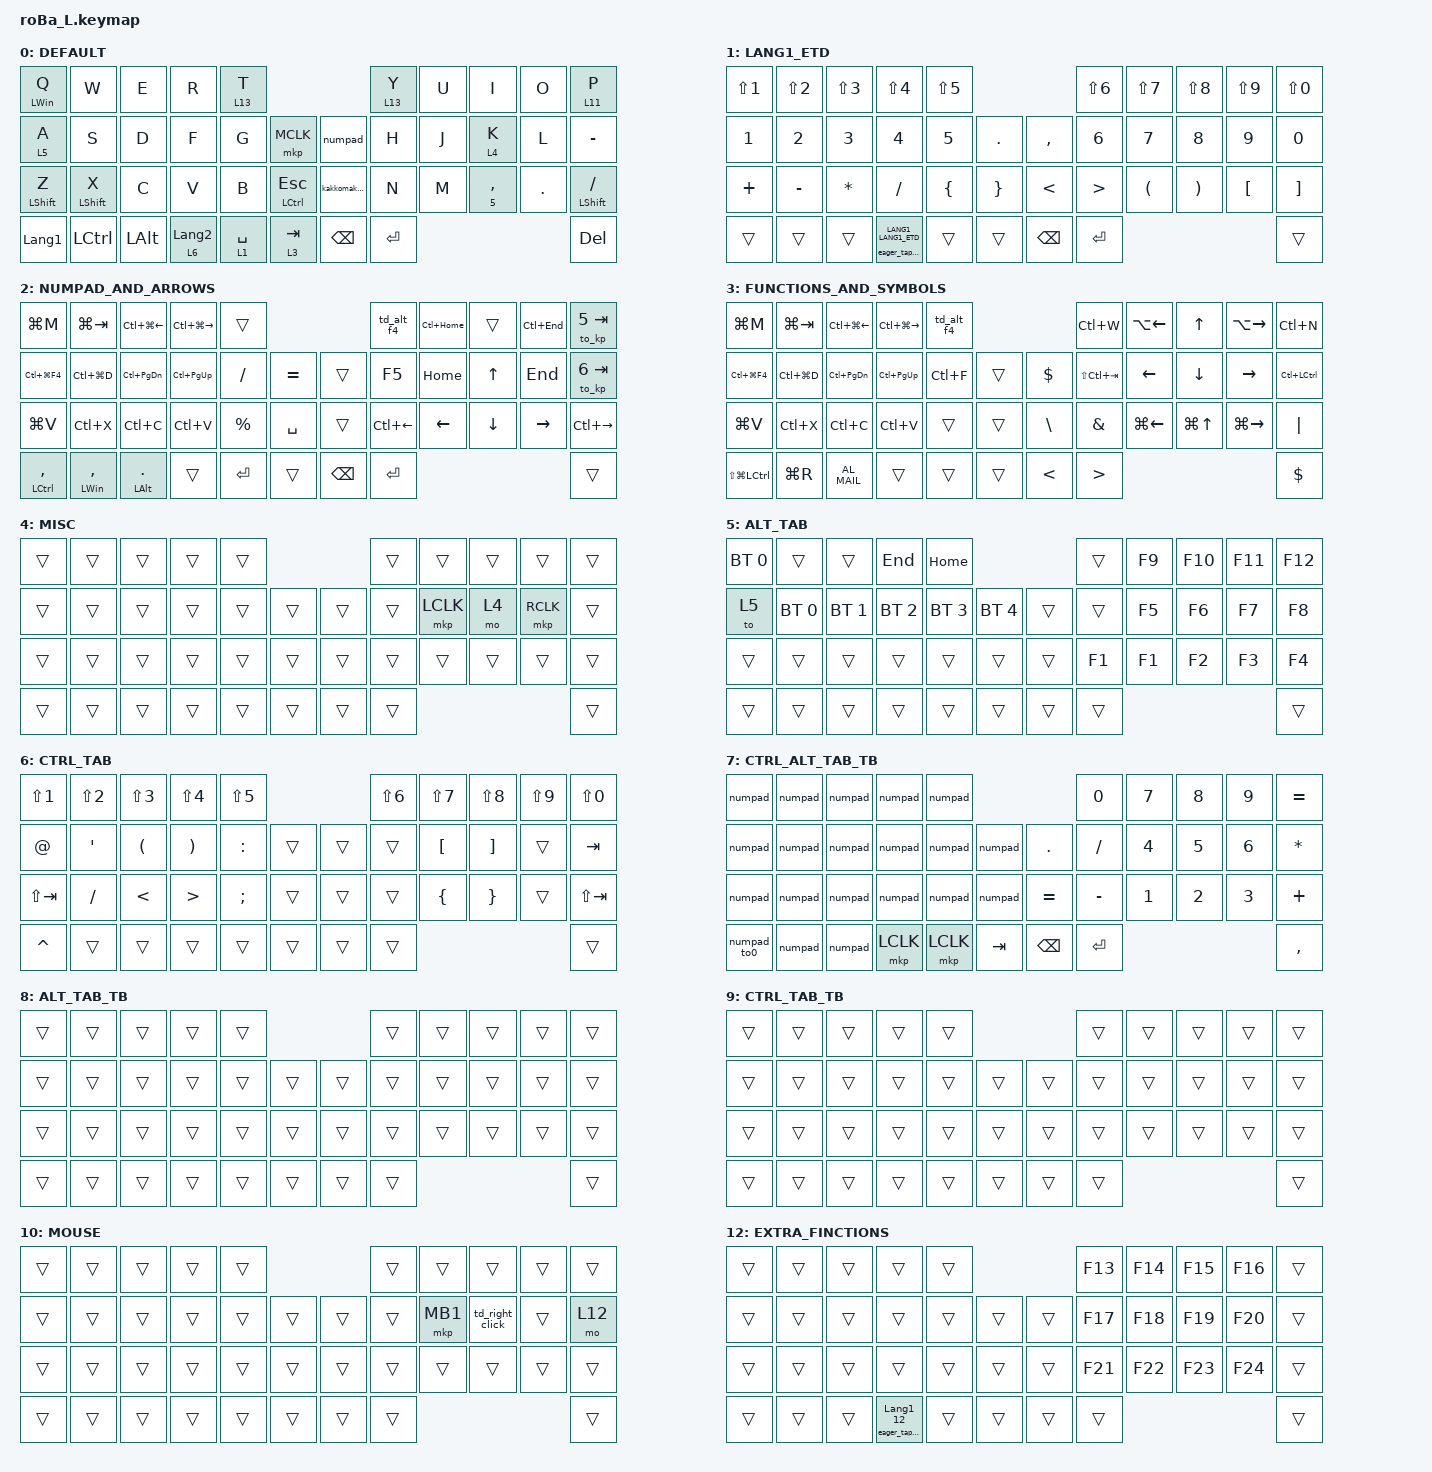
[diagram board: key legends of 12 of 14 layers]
#define ZMK_POINTING_DEFAULT_SCRL_VAL 100

// #define ZMK_POINTING_DEFAULT_MOVE_VAL 700

#include <input/processors.dtsi>
#include <behaviors/rgbled_widget.dtsi>
#include <behaviors.dtsi>
#include <dt-bindings/zmk/backlight.h>
#include <dt-bindings/zmk/bt.h>
#include <dt-bindings/zmk/keys.h>
#include <dt-bindings/zmk/outputs.h>
#include <dt-bindings/zmk/pointing.h>

#define DEFAULT 0
#define LANG1_ETD 1
#define NUMPAD_AND_ARROWS 2
#define FUNCTIONS_AND_SYMBOLS 3
#define MISC 4
#define ALT_TAB 5
#define CTRL_TAB 6
#define CTRL_ALT_TAB_TB 7
#define ALT_TAB_TB 8
#define CTRL_TAB_TB 9
#define MOUSE 10
#define MEDIA 11
#define EXTRA_FINCTIONS 12
#define CONFIGURATION 13

&mt {
    tapping-term-ms = <200>;
    quick-tap-ms = <250>;
    flavor = "balanced";
};

&lt {
    tapping-term-ms = <200>;
    quick-tap-ms = <250>;
    flavor = "balanced";
};

&sk { release-after-ms = <700>; };

&sl { release-after-ms = <1000>; };

&mkp_input_listener { input-processors = <&zip_temp_layer MOUSE 10000>; };

/ {
    layer_listeners {
        compatible = "zmk,layer-listeners";

        release_alt {
            layers = <ALT_TAB ALT_TAB_TB>;
            bindings = <&kt_on LEFT_ALT &kt_off LEFT_ALT>;
        };

        release_ctrl {
            layers = <CTRL_TAB CTRL_TAB_TB>;
            bindings = <&kt_on LCTRL &kt_off LCTRL>;
        };

        // AML_indicator {
        //     layers = <MOUSE>;
        //     bindings = <&kp LS(LA(LC(LG(H)))) &kp LS(LA(LC(LG(H))))>;
        // };
        // AML {
        //     layers = <MOUSE>;
        //     bindings = <&to MOUSE &none>;
        // };
    };

    combos {
        compatible = "zmk,combos";

        eq {
            bindings = <&kp EQUAL>;
            key-positions = <0 1>;
            layers = <2>;
        };

        Escape {
            bindings = <&kp ESCAPE>;
            key-positions = <0 1>;
        };

        hat {
            bindings = <&kp CARET>;
            key-positions = <10 11>;
            layers = <2>;
        };

        L_click {
            bindings = <&mkp LCLK>;
            key-positions = <18 19>;
            layers = <10>;
        };

        caps_word {
            bindings = <&caps_word>;
            key-positions = <22 33>;
        };

        dot_slash_backslash {
            bindings = <&kp BACKSLASH>;
            key-positions = <33 32>;
        };

        R_click {
            bindings = <&mkp RCLK>;
            key-positions = <19 20>;
        };
    };

    macros {
        /omit-if-no-ref/


        /omit-if-no-ref/


        /omit-if-no-ref/


        /omit-if-no-ref/


        /omit-if-no-ref/


        /omit-if-no-ref/

        mo_exit_alttab: mo_exit_alttab_ctrltab {
            compatible = "zmk,behavior-macro-one-param";
            wait-ms = <0>;
            tap-ms = <0>;
            #binding-cells = <1>;
            bindings =
                <&macro_press>,
                <&macro_param_1to1 &mo MACRO_PLACEHOLDER>,
                <&macro_tap>,
                <&macro_pause_for_release>,
                <&macro_release>,
                <&macro_param_1to1 &mo MACRO_PLACEHOLDER>,
                <&macro_tap>,
                <&tog_off ALT_TAB &tog_off CTRL_TAB>;
        };

        /omit-if-no-ref/

        kp_to: kp_to {
            compatible = "zmk,behavior-macro-two-param";
            wait-ms = <0>;
            tap-ms = <0>;
            #binding-cells = <2>;
            bindings = <&macro_param_1to1 &kp MACRO_PLACEHOLDER &macro_param_2to1 &to MACRO_PLACEHOLDER>;
        };

        /omit-if-no-ref/

        to_kp: to_kp {
            compatible = "zmk,behavior-macro-two-param";
            #binding-cells = <2>;
            bindings = <&macro_param_1to1 &to MACRO_PLACEHOLDER &macro_param_2to1 &kp MACRO_PLACEHOLDER>;
        };

        /omit-if-no-ref/

        zoom_in: zoom_in {
            compatible = "zmk,behavior-macro";
            #binding-cells = <0>;
            bindings = <&kt_on LCTRL &msc SCRL_UP &kt_off LCTRL>;
        };

        /omit-if-no-ref/

        zoom_out: zoom_out {
            compatible = "zmk,behavior-macro";
            #binding-cells = <0>;
            bindings = <&kt_on LCTRL &msc SCRL_DOWN &kt_off LCTRL>;
        };

        /omit-if-no-ref/

        eager_tap_dance: eager_tap_dance {
            compatible = "zmk,behavior-macro-two-param";
            #binding-cells = <2>;
            bindings =
                <&macro_press>,
                <&macro_param_1to1 &kp MACRO_PLACEHOLDER>,
                <&macro_pause_for_release>,
                <&macro_release>,
                <&macro_param_1to1 &kp MACRO_PLACEHOLDER>,
                <&macro_tap>,
                <&exit_AML &macro_param_2to1 &sl_250 MACRO_PLACEHOLDER>;
        };
    };

    behaviors {
        /omit-if-no-ref/

        tog_on: toggle_layer_on {
            compatible = "zmk,behavior-toggle-layer";
            #binding-cells = <1>;
            display-name = "Toggle Layer On";
            toggle-mode = "on";
        };

        /omit-if-no-ref/

        tog_off: toggle_layer_off {
            compatible = "zmk,behavior-toggle-layer";
            #binding-cells = <1>;
            display-name = "Toggle Layer Off";
            toggle-mode = "off";
        };

        /omit-if-no-ref/

        kt_on: key_toggle_on_only {
            compatible = "zmk,behavior-key-toggle";
            #binding-cells = <1>;
            display-name = "Key Toggle On";
            toggle-mode = "on";
        };

        /omit-if-no-ref/

        kt_off: key_toggle_off_only {
            compatible = "zmk,behavior-key-toggle";
            #binding-cells = <1>;
            display-name = "Key Toggle Off";
            toggle-mode = "off";
        };

        /omit-if-no-ref/

        td_right_click: td_right_click {
            compatible = "zmk,behavior-tap-dance";
            #binding-cells = <0>;
            bindings = <&mkp RCLK>, <&kp LC(W)>;

            tapping-term-ms = <250>;
        };

        /omit-if-no-ref/

        td_colon: td_colon {
            compatible = "zmk,behavior-tap-dance";
            #binding-cells = <0>;
            bindings = <&kp COLON>, <&kp SEMICOLON>;

            tapping-term-ms = <250>;
        };

        /omit-if-no-ref/

        td_q_escape: td_q_escape {
            compatible = "zmk,behavior-tap-dance";
            #binding-cells = <0>;
            tapping-term-ms = <250>;
            bindings = <&kp Q>, <&kp ESCAPE>;
        };

        /omit-if-no-ref/

        td_ZenkakuHankaku: td_ZenkakuHankaku {
            compatible = "zmk,behavior-tap-dance";

            // compatible = "zmk,behavior-eager-tap-dance";

            #binding-cells = <0>;
            tapping-term-ms = <250>;
            bindings = <&kp LANGUAGE_2>, <&kp LANGUAGE_1>;
        };

        /omit-if-no-ref/

        td_ZenkakuHankaku_exit_AML: td_ZenkakuHankaku_exit_AML {
            wait-ms = <0>;
            tap-ms = <0>;
            compatible = "zmk,behavior-macro";
            #binding-cells = <0>;
            bindings = <&td_ZenkakuHankaku &exit_AML>;
        };

        /omit-if-no-ref/

        alt_tab: alt_tab {
            compatible = "zmk,behavior-macro-two-param";
            #binding-cells = <2>;
            bindings = <&macro_param_1to1 &kt_on MACRO_PLACEHOLDER &macro_param_2to1 &kp MACRO_PLACEHOLDER &macro_param_1to1 &sk MACRO_PLACEHOLDER &macro_param_1to1 &kt_off MACRO_PLACEHOLDER>;
        };

        /omit-if-no-ref/

        windows_sleep: windows_sleep {
            compatible = "zmk,behavior-macro";
            wait-ms = <200>;
            tap-ms = <100>;
            #binding-cells = <0>;
            bindings = <&kp LG(X) &kp U &kp S>;
        };

        /omit-if-no-ref/

        screensot_save: screensot_save {
            compatible = "zmk,behavior-macro";
            #binding-cells = <0>;
            bindings = <&kp LS(F11)>;
            label = "SCREENSOT_SAVE";
        };

        numpad: numpad {
            compatible = "zmk,behavior-macro";
            #binding-cells = <0>;
            bindings = <&kp KP_NUMLOCK &to 7>;
            label = "NUMPAD";
        };

        numpad_to0: numpad_to0 {
            compatible = "zmk,behavior-macro";
            #binding-cells = <0>;
            bindings = <&kp KP_NUMLOCK &to 0>;
            label = "NUMPAD_TO0";
        };

        kakkomakuro: kakkomakuro {
            compatible = "zmk,behavior-macro";
            #binding-cells = <0>;
            bindings = <&kp LANGUAGE_2 &kp LEFT_PARENTHESIS &kp RIGHT_PARENTHESIS &kp ENTER &kp LEFT_ARROW>;
            label = "KAKKOMAKURO";
        };

        new_macro: new_macro {
            compatible = "zmk,behavior-macro";
            #binding-cells = <0>;
            bindings = <&none>;
            label = "NEW_MACRO";
        };

        /omit-if-no-ref/

        screenshot_copy: screenshot_copy {
            compatible = "zmk,behavior-mod-morph";
            bindings = <&kp LA(PRINTSCREEN)>, <&kp LA(PRINTSCREEN)>;

            #binding-cells = <0>;
            mods = <(MOD_LSFT|MOD_LALT)>;
            keep-mods = <(MOD_LALT)>;
        };

        /omit-if-no-ref/

        mod_morph_exclamation: mod_morph_exclamation {
            compatible = "zmk,behavior-mod-morph";
            bindings = <&kp COMMA>, <&kp EXCL>;

            #binding-cells = <0>;
            mods = <(MOD_LSFT)>;
        };

        /omit-if-no-ref/

        mod_morph_question: mod_morph_question {
            compatible = "zmk,behavior-mod-morph";
            bindings = <&kp PERIOD>, <&kp QUESTION>;

            #binding-cells = <0>;
            mods = <(MOD_LSFT)>;
        };

        /omit-if-no-ref/

        mod_morph_slash: mod_morph_slash {
            compatible = "zmk,behavior-mod-morph";
            bindings = <&kp SLASH>, <&kp BACKSLASH>;

            #binding-cells = <0>;
            mods = <(MOD_LSFT)>;
        };

        /omit-if-no-ref/

        td_alt_f4: td_alt_f4 {
            compatible = "zmk,behavior-tap-dance";
            #binding-cells = <0>;
            bindings = <&kp F4>, <&kp LA(F4)>;

            tapping-term-ms = <250>;
        };

        /omit-if-no-ref/

        lt_exit_AML: lt_exit_AML {
            compatible = "zmk,behavior-hold-tap";
            bindings = <&mo_exit_AML>, <&kp_exit_AML>;

            #binding-cells = <2>;
            tapping-term-ms = <200>;
            quick-tap-ms = <200>;
            flavor = "balanced";
        };

        /omit-if-no-ref/

        lt_exit_AML_on_hold: lt_exit_AML_on_hold {
            compatible = "zmk,behavior-hold-tap";
            bindings = <&mo_exit_AML>, <&kp>;

            #binding-cells = <2>;
            tapping-term-ms = <200>;
            quick-tap-ms = <200>;
            flavor = "balanced";
        };

        /omit-if-no-ref/

        lt_exit_alttab: lt_exit_alttab_ctrltab_on_hold_release {
            compatible = "zmk,behavior-hold-tap";
            bindings = <&mo_exit_alttab>, <&kp>;

            #binding-cells = <2>;
            tapping-term-ms = <200>;
            quick-tap-ms = <200>;
            flavor = "balanced";
        };

        /omit-if-no-ref/

        mt_exit_AML: mt_exit_AML {
            compatible = "zmk,behavior-hold-tap";
            bindings = <&mod_exit_AML>, <&kp_exit_AML>;

            #binding-cells = <2>;
            tapping-term-ms = <200>;
            flavor = "balanced";
            quick-tap-ms = <200>;
        };

        /omit-if-no-ref/

        mt_exit_AML_on_tap: mt_exit_AML_on_tap {
            compatible = "zmk,behavior-hold-tap";
            bindings = <&kp>, <&kp_exit_AML>;

            #binding-cells = <2>;
            tapping-term-ms = <200>;
            flavor = "balanced";
            quick-tap-ms = <200>;
        };

        /omit-if-no-ref/

        encoder_zoom: encoder_zoom {
            compatible = "zmk,behavior-sensor-rotate";
            #sensor-binding-cells = <0>;
            bindings = <&zoom_out>, <&zoom_in>;
        };

        /omit-if-no-ref/

        encoder_volume: encoder_volume {
            compatible = "zmk,behavior-sensor-rotate";
            #sensor-binding-cells = <0>;
            bindings = <&kp C_VOLUME_DOWN>, <&kp C_VOLUME_UP>;
        };

        /omit-if-no-ref/

        sl_250: sl_250 {
            compatible = "zmk,behavior-sticky-key";
            bindings = <&mo>;
            #binding-cells = <1>;
            release-after-ms = <250>;
        };

        /omit-if-no-ref/

        td_bt_clear: td_bt_clear {
            compatible = "zmk,behavior-tap-dance";
            #binding-cells = <0>;
            bindings = <&none>, <&none>, <&bt BT_CLR>;

            tapping-term-ms = <250>;
        };

        /omit-if-no-ref/

        td_bt_clear_all: td_bt_clear_all {
            compatible = "zmk,behavior-tap-dance";
            #binding-cells = <0>;
            tapping-term-ms = <250>;
            bindings = <&none>, <&none>, <&bt BT_CLR_ALL>;
        };

        /omit-if-no-ref/

        td_copy_paste: td_copy_paste {
            compatible = "zmk,behavior-tap-dance";
            #binding-cells = <0>;
            bindings = <&kp_exit_AML LC(C)>, <&kp_exit_AML LC(V)>;

            tapping-term-ms = <250>;
        };

        scroll: scroll {
            compatible = "zmk,behavior-sensor-rotate";
            label = "SCROLL";
            #sensor-binding-cells = <0>;
            bindings = <&msc MOVE_X(-5)>, <&msc MOVE_X(5)>;
        };
    };

    keymap {
        compatible = "zmk,keymap";

        DEFAULT {
            bindings = <
&mt LWIN Q                        &kp W             &kp E         &kp R             &lt 13 T                                          &lt 13 Y   &kp U  &kp I                    &kp O    &lt 11 P
&lt 5 A                           &kp S             &kp D         &kp F             &kp G        &mkp MCLK             &numpad        &kp H      &kp J  &lt 4 K                  &kp L    &kp MINUS
&mt_exit_AML_on_tap LEFT_SHIFT Z  &mt LEFT_SHIFT X  &kp C         &kp V             &kp B        &mt LCTRL ESCAPE      &kakkomakuro   &kp N      &kp M  &lt_exit_alttab 5 COMMA  &kp DOT  &mt LEFT_SHIFT SLASH
&kp LANGUAGE_1                    &kp LEFT_CONTROL  &kp LEFT_ALT  &lt 6 LANGUAGE_2  &lt 1 SPACE  &lt 3 TAB             &kp BACKSPACE  &kp ENTER                                           &kp DEL
            >;

            sensor-bindings = <&scroll>;
        };

        LANG1_ETD {
            bindings = <
&kp LS(N1)  &kp LS(N2)  &kp LS(N3)    &kp LS(NUMBER_4)                  &kp LS(N5)                                          &kp LS(N6)        &kp LS(N7)            &kp LS(N8)             &kp LS(NUMBER_9)  &kp LS(N0)
&kp N1      &kp N2      &kp N3        &kp N4                            &kp N5          &kp PERIOD           &kp COMMA      &kp N6            &kp NUMBER_7          &kp N8                 &kp N9            &kp N0
&kp PLUS    &kp MINUS   &kp ASTERISK  &kp SLASH                         &kp LEFT_BRACE  &kp RIGHT_BRACE      &kp LESS_THAN  &kp GREATER_THAN  &kp LEFT_PARENTHESIS  &kp RIGHT_PARENTHESIS  &kp LBKT          &kp RIGHT_BRACKET
&trans      &trans      &trans        &eager_tap_dance LANG1 LANG1_ETD  &trans          &trans               &kp BACKSPACE  &kp ENTER                                                                        &trans
            >;
        };

        NUMPAD_AND_ARROWS {
            bindings = <
&kp LG(M)        &kp LG(TAB)         &kp LC(LG(LEFT_ARROW))  &kp LC(LG(RIGHT_ARROW))  &trans                                     &td_alt_f4    &kp LC(HOME)  &trans        &kp LC(END)  &to_kp 5 TAB
&kp LC(LG(F4))   &kp LC(LG(D))       &kp LC(PAGE_DOWN)       &kp LC(PAGE_UP)          &kp SLASH    &kp EQUAL      &trans         &kp F5        &kp HOME      &kp UP_ARROW  &kp END      &to_kp 6 TAB
&kp LG(V)        &kp LC(X)           &kp LC(C)               &kp LC(V)                &kp PERCENT  &kp SPACE      &trans         &kp LC(LEFT)  &kp LEFT      &kp DOWN      &kp RIGHT    &kp LC(RIGHT)
&mt LCTRL COMMA  &mt LEFT_WIN COMMA  &mt LEFT_ALT PERIOD     &trans                   &kp ENTER    &trans         &kp BACKSPACE  &kp ENTER                                              &trans
            >;

            sensor-bindings =
                <&inc_dec_kp LC(PLUS) LC(MINUS)>,
                <&inc_dec_kp 0 0>;
        };

        FUNCTIONS_AND_SYMBOLS {
            bindings = <
&kp LG(M)          &kp LG(TAB)    &kp LC(LG(LEFT_ARROW))  &kp LC(LG(RIGHT_ARROW))  &td_alt_f4                             &kp LC(W)         &kp LA(LEFT_ARROW)  &kp UP_ARROW      &kp LA(RIGHT_ARROW)  &kp LC(N)
&kp LC(LG(F4))     &kp LC(LG(D))  &kp LC(PAGE_DOWN)       &kp LC(PAGE_UP)          &kp LC(F)   &trans      &kp DOLLAR     &kp LS(LC(TAB))   &kp LEFT_ARROW      &kp DOWN_ARROW    &kp RIGHT_ARROW      &kp LC(LEFT_CONTROL)
&kp LG(V)          &kp LC(X)      &kp LC(C)               &kp LC(V)                &trans      &trans      &kp BSLH       &kp AMPERSAND     &kp LG(LEFT_ARROW)  &kp LG(UP_ARROW)  &kp LG(RIGHT_ARROW)  &kp PIPE
&kp LS(LG(LCTRL))  &kp LG(R)      &kp C_AL_MAIL           &trans                   &trans      &trans      &kp LESS_THAN  &kp GREATER_THAN                                                             &kp DOLLAR
            >;
        };

        MISC {
            bindings = <
&trans  &trans  &trans  &trans  &trans                      &trans  &trans     &trans  &trans     &trans
&trans  &trans  &trans  &trans  &trans  &trans      &trans  &trans  &mkp LCLK  &mo 4   &mkp RCLK  &trans
&trans  &trans  &trans  &trans  &trans  &trans      &trans  &trans  &trans     &trans  &trans     &trans
&trans  &trans  &trans  &trans  &trans  &trans      &trans  &trans                                &trans
            >;

            sensor-bindings = <&scroll>, <&inc_dec_kp 0 0>;
        };

        ALT_TAB {
            bindings = <
&bt BT_SEL 0  &trans        &trans        &kp END       &kp HOME                                &trans  &kp F9  &kp F10  &kp F11  &kp F12
&to 5         &bt BT_SEL 0  &bt BT_SEL 1  &bt BT_SEL 2  &bt BT_SEL 3  &bt BT_SEL 4      &trans  &trans  &kp F5  &kp F6   &kp F7   &kp F8
&trans        &trans        &trans        &trans        &trans        &trans            &trans  &kp F1  &kp F1  &kp F2   &kp F3   &kp F4
&trans        &trans        &trans        &trans        &trans        &trans            &trans  &trans                            &trans
            >;
        };

        CTRL_TAB {
            bindings = <
&kp LS(N1)   &kp LS(N2)  &kp LS(N3)            &kp LS(N4)             &kp LS(N5)                         &kp LS(N6)  &kp LS(N7)        &kp LS(N8)         &kp LS(N9)  &kp LS(N0)
&kp AT_SIGN  &kp SQT     &kp LEFT_PARENTHESIS  &kp RIGHT_PARENTHESIS  &kp COLON      &trans      &trans  &trans      &kp LEFT_BRACKET  &kp RIGHT_BRACKET  &trans      &kp TAB
&kp LS(TAB)  &kp SLASH   &kp LESS_THAN         &kp GREATER_THAN       &kp SEMICOLON  &trans      &trans  &trans      &kp LEFT_BRACE    &kp RIGHT_BRACE    &trans      &kp LS(TAB)
&kp CARET    &trans      &trans                &trans                 &trans         &trans      &trans  &trans                                                       &trans
            >;

            sensor-bindings = <&encoder_zoom>;
        };

        CTRL_ALT_TAB_TB {
            bindings = <
&numpad      &numpad  &numpad  &numpad    &numpad                                &kp NUMBER_0  &kp N7        &kp N8        &kp N9        &kp EQUAL
&numpad      &numpad  &numpad  &numpad    &numpad    &numpad      &kp PERIOD     &kp SLASH     &kp NUMBER_4  &kp N5        &kp NUMBER_6  &kp ASTERISK
&numpad      &numpad  &numpad  &numpad    &numpad    &numpad      &kp EQUAL      &kp MINUS     &kp N1        &kp NUMBER_2  &kp NUMBER_3  &kp PLUS
&numpad_to0  &numpad  &numpad  &mkp LCLK  &mkp LCLK  &kp TAB      &kp BACKSPACE  &kp ENTER                                               &kp COMMA
            >;
        };

        ALT_TAB_TB {
            bindings = <
&trans  &trans  &trans  &trans  &trans                      &trans  &trans  &trans  &trans  &trans
&trans  &trans  &trans  &trans  &trans  &trans      &trans  &trans  &trans  &trans  &trans  &trans
&trans  &trans  &trans  &trans  &trans  &trans      &trans  &trans  &trans  &trans  &trans  &trans
&trans  &trans  &trans  &trans  &trans  &trans      &trans  &trans                          &trans
            >;
        };

        CTRL_TAB_TB {
            bindings = <
&trans  &trans  &trans  &trans  &trans                      &trans  &trans  &trans  &trans  &trans
&trans  &trans  &trans  &trans  &trans  &trans      &trans  &trans  &trans  &trans  &trans  &trans
&trans  &trans  &trans  &trans  &trans  &trans      &trans  &trans  &trans  &trans  &trans  &trans
&trans  &trans  &trans  &trans  &trans  &trans      &trans  &trans                          &trans
            >;
        };

        MOUSE {
            bindings = <
&trans  &trans  &trans  &trans  &trans                      &trans  &trans    &trans           &trans  &trans
&trans  &trans  &trans  &trans  &trans  &trans      &trans  &trans  &mkp MB1  &td_right_click  &trans  &mo 12
&trans  &trans  &trans  &trans  &trans  &trans      &trans  &trans  &trans    &trans           &trans  &trans
&trans  &trans  &trans  &trans  &trans  &trans      &trans  &trans                                     &trans
            >;
        };

        MEDIA {
            bindings = <
&trans  &trans     &trans  &trans  &trans                      &kp C_PREV         &kp C_PLAY_PAUSE   &kp C_NEXT       &trans  &trans
&trans  &trans     &trans  &trans  &trans  &trans      &trans  &kp C_VOLUME_DOWN  &kp C_MUTE         &kp C_VOLUME_UP  &trans  &trans
&trans  &trans     &trans  &trans  &trans  &trans      &trans  &trans             &kp LS(LA(LC(M)))  &trans           &trans  &trans
&trans  &bl BL_ON  &trans  &trans  &trans  &trans      &trans  &trans                                                         &trans
            >;
        };

        EXTRA_FINCTIONS {
            bindings = <
&trans  &trans  &trans  &trans                          &trans                      &kp F13  &kp F14  &kp F15  &kp F16  &trans
&trans  &trans  &trans  &trans                          &trans  &trans      &trans  &kp F17  &kp F18  &kp F19  &kp F20  &trans
&trans  &trans  &trans  &trans                          &trans  &trans      &trans  &kp F21  &kp F22  &kp F23  &kp F24  &trans
&trans  &trans  &trans  &eager_tap_dance LANGUAGE_1 12  &trans  &trans      &trans  &trans                              &trans
            >;
        };

        CONFIGURATION {
            bindings = <
&bootloader  &sys_reset  &none  &none  &none                            &none         &none         &out OUT_TOG  &sys_reset      &bootloader
&none        &none       &none  &none  &none  &trans      &ind_con      &ind_bat      &none         &none         &windows_sleep  &none
&none        &none       &none  &none  &none  &none       &bt BT_SEL 0  &bt BT_SEL 1  &bt BT_SEL 2  &bt BT_SEL 3  &bt BT_SEL 4    &td_bt_clear
&none        &none       &none  &none  &none  &none       &none         &none                                                     &td_bt_clear_all
            >;
        };
    };
};
